# HC32F120 register map
File version: 1.0
CPU: CM0+ r0p1, little endian, no MPU, no FPU, 2 interrupt priority bits
Registers are 32-bit, read-write, reset 0x0 unless marked. A register's access mark holds for its fields unless they carry their own. Offsets are from the block's base; [hi:lo] are bit positions; {n}, {i} and the like mark numbered series; 'fields as' and 'values as' point back to an identical list.

## GPIO
Base 0x40013800
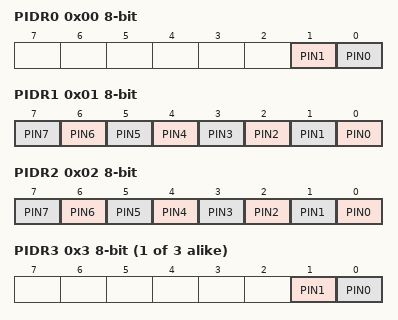
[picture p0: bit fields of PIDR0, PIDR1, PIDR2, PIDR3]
0x00 PIDR0 8-bit ro
  [1] PIN1, [0] PIN0
0x01 PIDR1 8-bit ro
  [n] PIN{n} (n=0..7)
0x02 PIDR2 8-bit ro
  [n] PIN{n} (n=0..7)
{0x0+i} PIDR{i} 8-bit ro (i=3..5)
  [1] PIN1, [0] PIN0
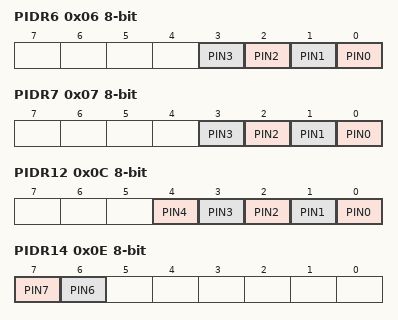
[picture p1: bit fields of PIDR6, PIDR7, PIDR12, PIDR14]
0x06 PIDR6 8-bit ro
  [n] PIN{n} (n=0..3)
0x07 PIDR7 8-bit ro
  [n] PIN{n} (n=0..3)
0x0C PIDR12 8-bit ro
  [n] PIN{n} (n=0..4)
0x0D PIDR13 8-bit ro
  [7] PIN7
0x0E PIDR14 8-bit ro
  [7] PIN7, [6] PIN6
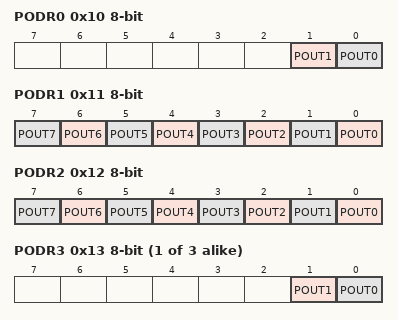
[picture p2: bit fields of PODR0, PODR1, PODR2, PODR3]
0x10 PODR0 8-bit
  [1] POUT1, [0] POUT0
0x11 PODR1 8-bit
  [n] POUT{n} (n=0..7)
0x12 PODR2 8-bit
  [n] POUT{n} (n=0..7)
{0x10+i} PODR{i} 8-bit (i=3..5)
  [1] POUT1, [0] POUT0
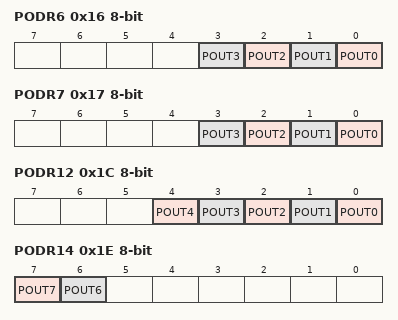
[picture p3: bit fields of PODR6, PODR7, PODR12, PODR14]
0x16 PODR6 8-bit
  [n] POUT{n} (n=0..3)
0x17 PODR7 8-bit
  [n] POUT{n} (n=0..3)
0x1C PODR12 8-bit
  [n] POUT{n} (n=0..4)
0x1D PODR13 8-bit
  [7] POUT7
0x1E PODR14 8-bit
  [7] POUT7, [6] POUT6
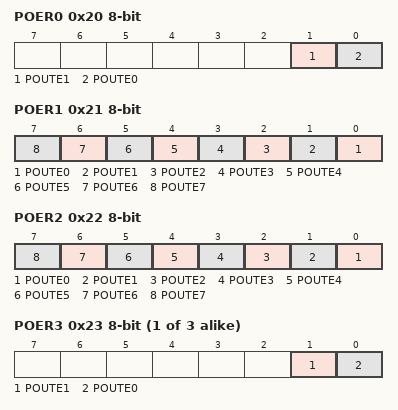
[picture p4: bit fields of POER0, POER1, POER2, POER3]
0x20 POER0 8-bit
  [1] POUTE1, [0] POUTE0
0x21 POER1 8-bit
  [n] POUTE{n} (n=0..7)
0x22 POER2 8-bit
  [n] POUTE{n} (n=0..7)
{0x20+i} POER{i} 8-bit (i=3..5)
  [1] POUTE1, [0] POUTE0
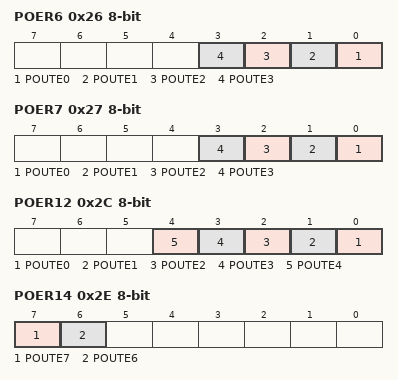
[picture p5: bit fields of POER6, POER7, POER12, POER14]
0x26 POER6 8-bit
  [n] POUTE{n} (n=0..3)
0x27 POER7 8-bit
  [n] POUTE{n} (n=0..3)
0x2C POER12 8-bit
  [n] POUTE{n} (n=0..4)
0x2D POER13 8-bit
  [7] POUTE7
0x2E POER14 8-bit
  [7] POUTE7, [6] POUTE6
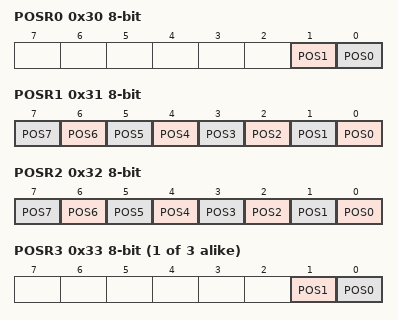
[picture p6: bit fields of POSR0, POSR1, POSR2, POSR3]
0x30 POSR0 8-bit wo
  [1] POS1, [0] POS0
0x31 POSR1 8-bit wo
  [n] POS{n} (n=0..7)
0x32 POSR2 8-bit wo
  [n] POS{n} (n=0..7)
{0x30+i} POSR{i} 8-bit wo (i=3..5)
  [1] POS1, [0] POS0
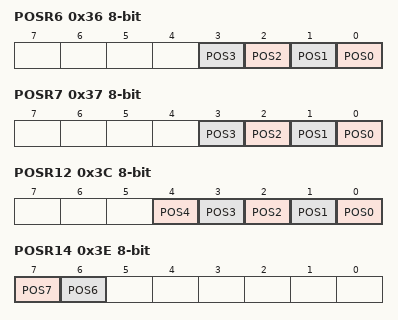
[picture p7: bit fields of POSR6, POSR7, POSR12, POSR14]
0x36 POSR6 8-bit wo
  [n] POS{n} (n=0..3)
0x37 POSR7 8-bit wo
  [n] POS{n} (n=0..3)
0x3C POSR12 8-bit wo
  [n] POS{n} (n=0..4)
0x3D POSR13 8-bit wo
  [7] POS7
0x3E POSR14 8-bit wo
  [7] POS7, [6] POS6
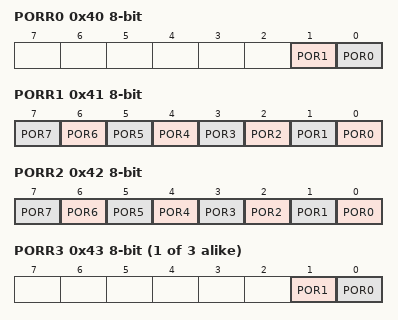
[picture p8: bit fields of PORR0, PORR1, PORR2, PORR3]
0x40 PORR0 8-bit wo
  [1] POR1, [0] POR0
0x41 PORR1 8-bit wo
  [n] POR{n} (n=0..7)
0x42 PORR2 8-bit wo
  [n] POR{n} (n=0..7)
{0x40+i} PORR{i} 8-bit wo (i=3..5)
  [1] POR1, [0] POR0
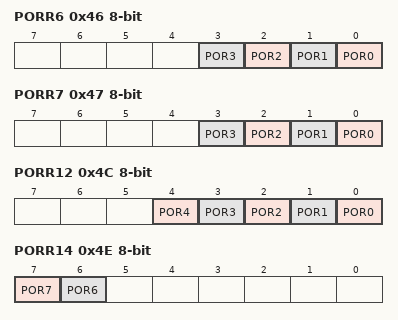
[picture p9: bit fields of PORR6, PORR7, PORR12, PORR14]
0x46 PORR6 8-bit wo
  [n] POR{n} (n=0..3)
0x47 PORR7 8-bit wo
  [n] POR{n} (n=0..3)
0x4C PORR12 8-bit wo
  [n] POR{n} (n=0..4)
0x4D PORR13 8-bit wo
  [7] POR7
0x4E PORR14 8-bit wo
  [7] POR7, [6] POR6
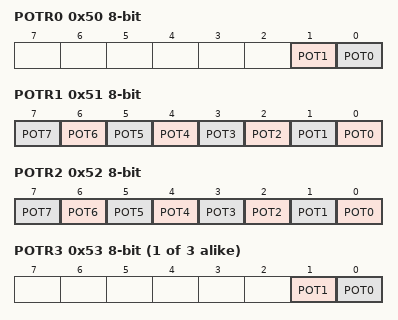
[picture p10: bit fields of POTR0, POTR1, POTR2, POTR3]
0x50 POTR0 8-bit wo
  [1] POT1, [0] POT0
0x51 POTR1 8-bit wo
  [n] POT{n} (n=0..7)
0x52 POTR2 8-bit wo
  [n] POT{n} (n=0..7)
{0x50+i} POTR{i} 8-bit wo (i=3..5)
  [1] POT1, [0] POT0
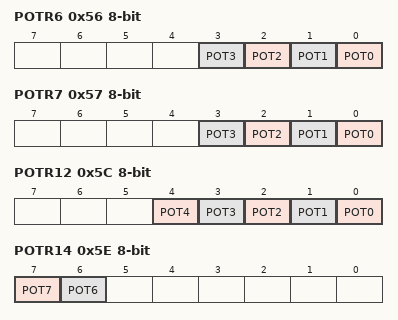
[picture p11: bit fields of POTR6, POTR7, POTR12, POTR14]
0x56 POTR6 8-bit wo
  [n] POT{n} (n=0..3)
0x57 POTR7 8-bit wo
  [n] POT{n} (n=0..3)
0x5C POTR12 8-bit wo
  [n] POT{n} (n=0..4)
0x5D POTR13 8-bit wo
  [7] POT7
0x5E POTR14 8-bit wo
  [7] POT7, [6] POT6
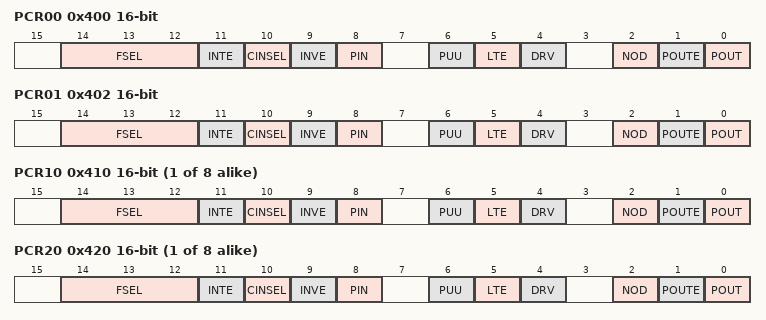
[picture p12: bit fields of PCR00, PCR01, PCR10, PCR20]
0x400 PCR00 16-bit
  [14:12] FSEL, [11] INTE, [10] CINSEL, [9] INVE, [8] PIN ro, [6] PUU, [5] LTE, [4] DRV, [2] NOD, [1] POUTE, [0] POUT
0x402 PCR01 16-bit
  fields as PCR00
{0x3FC+2i} PCR{i} 16-bit (i=10..17)
  fields as PCR00
{0x3F8+2i} PCR{i} 16-bit (i=20..27)
  fields as PCR00
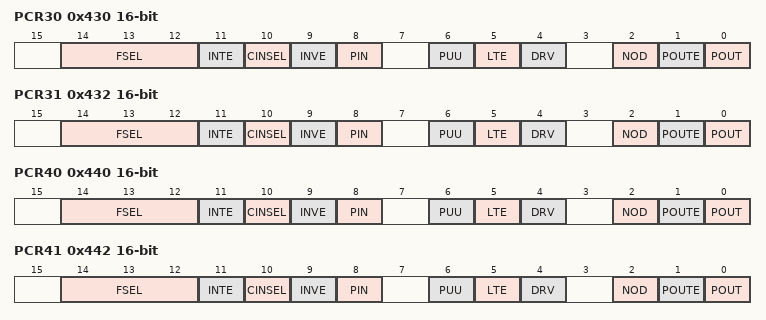
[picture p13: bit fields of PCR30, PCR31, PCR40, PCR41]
0x430 PCR30 16-bit
  fields as PCR00
0x432 PCR31 16-bit
  fields as PCR00
0x440 PCR40 16-bit
  fields as PCR00
0x442 PCR41 16-bit
  fields as PCR00
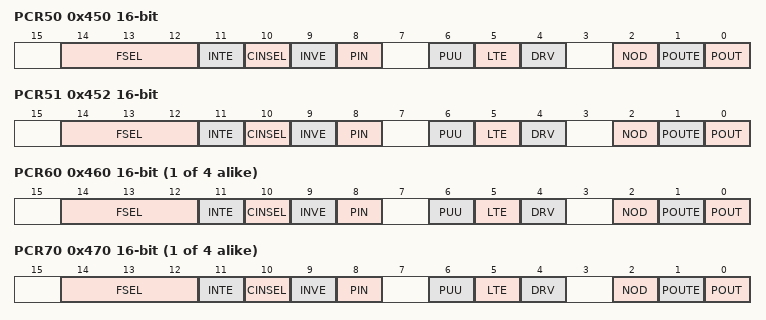
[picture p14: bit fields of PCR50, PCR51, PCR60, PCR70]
0x450 PCR50 16-bit
  fields as PCR00
0x452 PCR51 16-bit
  fields as PCR00
{0x3E8+2i} PCR{i} 16-bit (i=60..63)
  fields as PCR00
{0x3E4+2i} PCR{i} 16-bit (i=70..73)
  fields as PCR00
{0x3D0+2i} PCR{i} 16-bit (i=120..124)
  fields as PCR00
0x4DE PCR137 16-bit
  fields as PCR00
0x4EC PCR146 16-bit
  fields as PCR00
0x4EE PCR147 16-bit
  fields as PCR00
0x500 PSPCR 16-bit reset 0x3
  [1:0] SPFE
0x504 PCCR 16-bit reset 0x4000
  [15:14] RDWT
0x506 PINAER 16-bit
  [14] PINAE14, [13] PINAE13, [12] PINAE12, [n] PINAE{n} (n=0..7)
0x508 PWPR 16-bit
  [15:8] WP wo, [0] WE

## I2C
Base 0x40004800
0x00 CR1 reset 0x40
  [15] SWRST, [10] ACK, [9] STOP, [8] START, [7] RESTART, [6] GCEN, [5] FACKEN, [4] SMBHOSTEN, [3] SMBDEFAULTEN, [2] SMBALRTEN, [1] SMBUS, [0] PE
0x04 CR2
  [23] SMBALRTIE, [22] SMBHOSTIE, [21] SMBDEFAULTIE, [20] GENCALLIE, [12] NACKIE, [9] ARLOIE, [7] TEMPTYIE, [6] RFULLIE, [4] STOPIE, [3] TENDIE, [2] SLADDR1IE, [1] SLADDR0IE, [0] STARTIE
0x0C CR4 reset 0x300307
  [10] BUSWAIT
0x10 SLR0 reset 0x1000
  [15] ADDRMOD0, [12] SLADDR0EN, [9:0] SLADDR0
0x14 SLR1
  [15] ADDRMOD1, [12] SLADDR1EN, [9:0] SLADDR1
0x1C SR
  [23] SMBALRTF ro, [22] SMBHOSTF ro, [21] SMBDEFAULTF ro, [20] GENCALLF ro, [18] TRA, [17] BUSY ro, [16] MSL, [12] NACKF ro, [10] ACKRF ro, [9] ARLOF ro, [7] TEMPTYF ro, [6] RFULLF ro, [4] STOPF ro, [3] TENDF ro, [2] SLADDR1F ro, [1] SLADDR0F ro, [0] STARTF ro
0x20 CLR wo
  [23] SMBALRTFCLR, [22] SMBHOSTFCLR, [21] SMBDEFAULTFCLR, [20] GENCALLFCLR, [12] NACKFCLR, [9] ARLOFCLR, [7] TEMPTYFCLR, [6] RFULLFCLR, [4] STOPFCLR, [3] TENDFCLR, [2] SLADDR1FCLR, [1] SLADDR0FCLR, [0] STARTFCLR
0x24 DTR 8-bit reset 0xFF
  [7:0] DT
0x28 DRR 8-bit
  [7:0] DR
0x2C CCR reset 0x1F1F
  [18:16] CKDIV, [12:8] SHIGHW, [4:0] SLOWW
0x30 FLTR reset 0x10
  [5] ANFEN, [4] DNFEN, [1:0] DNF
